AUTOSAR XML (schema 4-0-3)
package /ComponentTypes
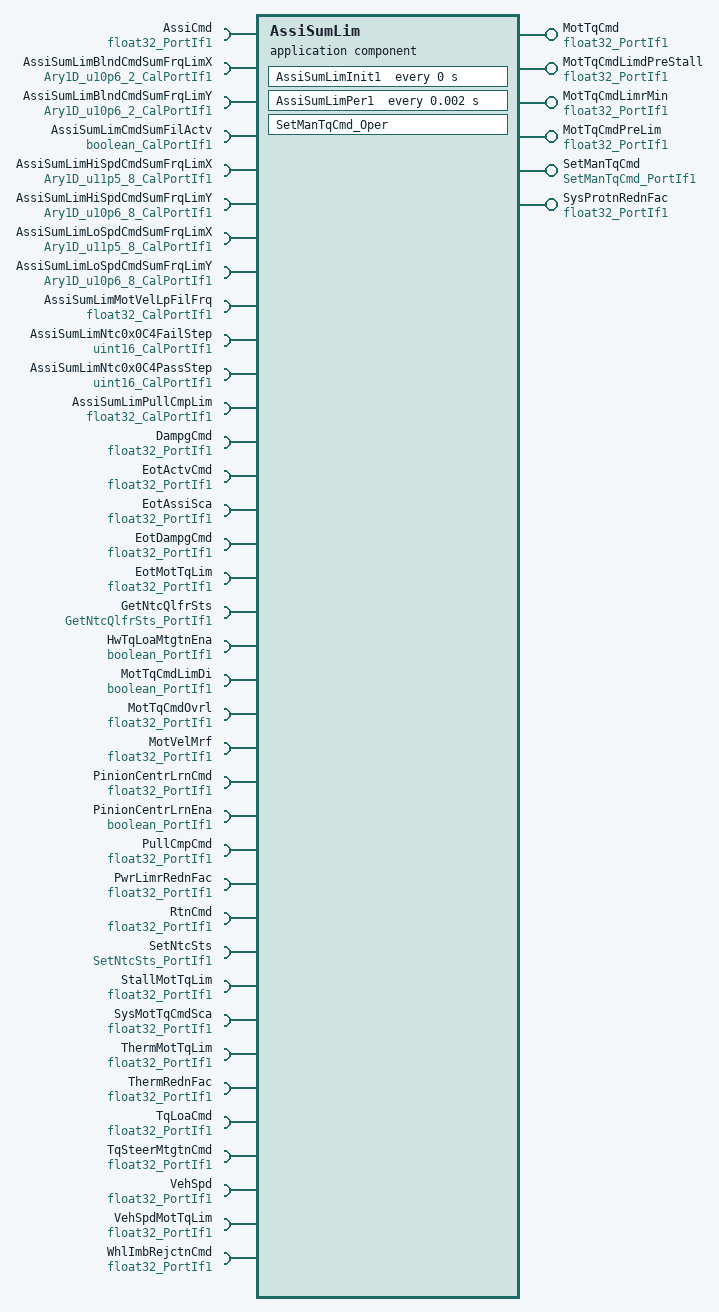
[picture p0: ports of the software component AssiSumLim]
  application sw component type AssiSumLim
    6 x provide port:
      MotTqCmd: nonqueued-sender-com-spec{data-element=Val, init-value=0}, provided-interface=float32_PortIf1
      MotTqCmdLimdPreStall: nonqueued-sender-com-spec{data-element=Val, init-value=0}, provided-interface=float32_PortIf1
      MotTqCmdLimrMin: nonqueued-sender-com-spec{data-element=Val, init-value=8.8}, provided-interface=float32_PortIf1
      MotTqCmdPreLim: nonqueued-sender-com-spec{data-element=Val, init-value=0}, provided-interface=float32_PortIf1
      SetManTqCmd: server-com-spec{operation=Oper, queue-length=1}, provided-interface=SetManTqCmd_PortIf1
      SysProtnRednFac: nonqueued-sender-com-spec{data-element=Val, init-value=0}, provided-interface=float32_PortIf1
    37 x require port:
      AssiCmd: nonqueued-receiver-com-spec{data-element=Val, filter=data-filter-type=ALWAYS, init-value=0}, required-interface=float32_PortIf1
      AssiSumLimBlndCmdSumFrqLimX: parameter-require-com-spec{init-value=[0, 32704], parameter=Ary1D}, required-interface=Ary1D_u10p6_2_CalPortIf1
      AssiSumLimBlndCmdSumFrqLimY: parameter-require-com-spec{init-value=[64, 0], parameter=Ary1D}, required-interface=Ary1D_u10p6_2_CalPortIf1
      AssiSumLimCmdSumFilActv: parameter-require-com-spec{init-value=1, parameter=Logl}, required-interface=boolean_CalPortIf1
      AssiSumLimHiSpdCmdSumFrqLimX: parameter-require-com-spec{init-value=[0, 3200, 8000, 9600, 16000, 24000, 32000, 43200], parameter=Ary1D}, required-interface=Ary1D_u11p5_8_CalPortIf1
      AssiSumLimHiSpdCmdSumFrqLimY: parameter-require-com-spec{init-value=8 x 32000, parameter=Ary1D}, required-interface=Ary1D_u10p6_8_CalPortIf1
      AssiSumLimLoSpdCmdSumFrqLimX: parameter-require-com-spec{init-value=[0, 3200, 8000, 9600, 16000, 24000, 32000, 43200], parameter=Ary1D}, required-interface=Ary1D_u11p5_8_CalPortIf1
      AssiSumLimLoSpdCmdSumFrqLimY: parameter-require-com-spec{init-value=8 x 32000, parameter=Ary1D}, required-interface=Ary1D_u10p6_8_CalPortIf1
      AssiSumLimMotVelLpFilFrq: parameter-require-com-spec{init-value=100, parameter=Val}, required-interface=float32_CalPortIf1
      AssiSumLimNtc0x0C4FailStep: parameter-require-com-spec{init-value=65535, parameter=Val}, required-interface=uint16_CalPortIf1
      AssiSumLimNtc0x0C4PassStep: parameter-require-com-spec{init-value=65535, parameter=Val}, required-interface=uint16_CalPortIf1
      AssiSumLimPullCmpLim: parameter-require-com-spec{init-value=8.8, parameter=Val}, required-interface=float32_CalPortIf1
      DampgCmd: nonqueued-receiver-com-spec{data-element=Val, filter=data-filter-type=ALWAYS, init-value=0}, required-interface=float32_PortIf1
      EotActvCmd: nonqueued-receiver-com-spec{data-element=Val, filter=data-filter-type=ALWAYS, init-value=0}, required-interface=float32_PortIf1
      EotAssiSca: nonqueued-receiver-com-spec{data-element=Val, filter=data-filter-type=ALWAYS, init-value=1}, required-interface=float32_PortIf1
      EotDampgCmd: nonqueued-receiver-com-spec{data-element=Val, filter=data-filter-type=ALWAYS, init-value=0}, required-interface=float32_PortIf1
      EotMotTqLim: nonqueued-receiver-com-spec{data-element=Val, filter=data-filter-type=ALWAYS, init-value=8.8}, required-interface=float32_PortIf1
      GetNtcQlfrSts: client-com-spec=Oper, required-interface=GetNtcQlfrSts_PortIf1
      HwTqLoaMtgtnEna: nonqueued-receiver-com-spec{data-element=Logl, filter=data-filter-type=ALWAYS, init-value=0}, required-interface=boolean_PortIf1
      MotTqCmdLimDi: nonqueued-receiver-com-spec{data-element=Logl, filter=data-filter-type=ALWAYS, init-value=0}, required-interface=boolean_PortIf1
      MotTqCmdOvrl: nonqueued-receiver-com-spec{data-element=Val, filter=data-filter-type=ALWAYS, init-value=0}, required-interface=float32_PortIf1
      MotVelMrf: nonqueued-receiver-com-spec{data-element=Val, filter=data-filter-type=ALWAYS, init-value=0}, required-interface=float32_PortIf1
      PinionCentrLrnCmd: nonqueued-receiver-com-spec{data-element=Val, filter=data-filter-type=ALWAYS, init-value=0}, required-interface=float32_PortIf1
      PinionCentrLrnEna: nonqueued-receiver-com-spec{data-element=Logl, filter=data-filter-type=ALWAYS, init-value=0}, required-interface=boolean_PortIf1
      PullCmpCmd: nonqueued-receiver-com-spec{data-element=Val, filter=data-filter-type=ALWAYS, init-value=0}, required-interface=float32_PortIf1
      PwrLimrRednFac: nonqueued-receiver-com-spec{data-element=Val, filter=data-filter-type=ALWAYS, init-value=0}, required-interface=float32_PortIf1
      RtnCmd: nonqueued-receiver-com-spec{data-element=Val, filter=data-filter-type=ALWAYS, init-value=0}, required-interface=float32_PortIf1
      SetNtcSts: client-com-spec=Oper, required-interface=SetNtcSts_PortIf1
      StallMotTqLim: nonqueued-receiver-com-spec{data-element=Val, filter=data-filter-type=ALWAYS, init-value=8.8}, required-interface=float32_PortIf1
      SysMotTqCmdSca: nonqueued-receiver-com-spec{data-element=Val, filter=data-filter-type=ALWAYS, init-value=1}, required-interface=float32_PortIf1
      ThermMotTqLim: nonqueued-receiver-com-spec{data-element=Val, filter=data-filter-type=ALWAYS, init-value=8.8}, required-interface=float32_PortIf1
      ThermRednFac: nonqueued-receiver-com-spec{data-element=Val, filter=data-filter-type=ALWAYS, init-value=0}, required-interface=float32_PortIf1
      TqLoaCmd: nonqueued-receiver-com-spec{data-element=Val, filter=data-filter-type=ALWAYS, init-value=0}, required-interface=float32_PortIf1
      TqSteerMtgtnCmd: nonqueued-receiver-com-spec{data-element=Val, filter=data-filter-type=ALWAYS, init-value=0}, required-interface=float32_PortIf1
      VehSpd: nonqueued-receiver-com-spec{data-element=Val, filter=data-filter-type=ALWAYS, init-value=0}, required-interface=float32_PortIf1
      VehSpdMotTqLim: nonqueued-receiver-com-spec{data-element=Val, filter=data-filter-type=ALWAYS, init-value=8.8}, required-interface=float32_PortIf1
      WhlImbRejctnCmd: nonqueued-receiver-com-spec{data-element=Val, filter=data-filter-type=ALWAYS, init-value=0}, required-interface=float32_PortIf1
    behavior AssiSumLim_InternalBehavior
      ar-typed-per-instance-memorys:
        data CmdSumInpPrev: sw-calibration-access=READ-ONLY, type=float32
        data CmdSumOutpPrev: sw-calibration-access=READ-ONLY, type=float32
        data MotVelFilLp: sw-calibration-access=READ-ONLY, type=FilLpRec1
      timing event AssiSumLim_InitEvent: start-on-event=AssiSumLimInit1, period=0
      timing event TMT_AssiSumLimPer1: start-on-event=AssiSumLimPer1, period=0.002
      operation invoked event OIT_SetManTqCmd_Oper_SetManTqCmd_Oper: start-on-event=SetManTqCmd_Oper, operation=SetManTqCmd.Oper
      explicit-inter-runnable-variables:
        data ProcdManTqCmd: type=float32, init-value=0
        data ProcdManTqCmdEna: type=boolean, init-value=0
      port-api-options:
        enable-take-address=false, indirect-api=false, port=AssiCmd
        enable-take-address=false, indirect-api=false, port=AssiSumLimBlndCmdSumFrqLimX
        enable-take-address=false, indirect-api=false, port=AssiSumLimBlndCmdSumFrqLimY
        enable-take-address=false, indirect-api=false, port=AssiSumLimCmdSumFilActv
        enable-take-address=false, indirect-api=false, port=AssiSumLimHiSpdCmdSumFrqLimX
        enable-take-address=false, indirect-api=false, port=AssiSumLimHiSpdCmdSumFrqLimY
        enable-take-address=false, indirect-api=false, port=AssiSumLimLoSpdCmdSumFrqLimX
        enable-take-address=false, indirect-api=false, port=AssiSumLimLoSpdCmdSumFrqLimY
        enable-take-address=false, indirect-api=false, port=AssiSumLimMotVelLpFilFrq
        enable-take-address=false, indirect-api=false, port=AssiSumLimNtc0x0C4FailStep
        enable-take-address=false, indirect-api=false, port=AssiSumLimNtc0x0C4PassStep
        enable-take-address=false, indirect-api=false, port=AssiSumLimPullCmpLim
        enable-take-address=false, indirect-api=false, port=DampgCmd
        enable-take-address=false, indirect-api=false, port=EotActvCmd
        enable-take-address=false, indirect-api=false, port=EotAssiSca
        enable-take-address=false, indirect-api=false, port=EotDampgCmd
        enable-take-address=false, indirect-api=false, port=EotMotTqLim
        enable-take-address=false, indirect-api=false, port=GetNtcQlfrSts
        enable-take-address=false, indirect-api=false, port=HwTqLoaMtgtnEna
        enable-take-address=false, indirect-api=false, port=MotTqCmd
        enable-take-address=false, indirect-api=false, port=MotTqCmdLimDi
        enable-take-address=false, indirect-api=false, port=MotTqCmdLimdPreStall
        enable-take-address=false, indirect-api=false, port=MotTqCmdLimrMin
        enable-take-address=false, indirect-api=false, port=MotTqCmdOvrl
        enable-take-address=false, indirect-api=false, port=MotTqCmdPreLim
        enable-take-address=false, indirect-api=false, port=RtnCmd
        enable-take-address=false, indirect-api=false, port=SetManTqCmd
        enable-take-address=false, indirect-api=false, port=SetNtcSts
        enable-take-address=false, indirect-api=false, port=SysMotTqCmdSca
        enable-take-address=false, indirect-api=false, port=SysProtnRednFac
        enable-take-address=false, indirect-api=false, port=TqLoaCmd
        enable-take-address=false, indirect-api=false, port=TqSteerMtgtnCmd
        enable-take-address=false, indirect-api=false, port=VehSpdMotTqLim
        enable-take-address=false, indirect-api=false, port=WhlImbRejctnCmd
      runnable AssiSumLimInit1
        sync call SC_SetNtcSts_Oper: operation=SetNtcSts.Oper, timeout=0
      runnable AssiSumLimPer1
        data-receive-point-by-arguments:
          24 x access:
            REC_AssiCmd_Val: accessed-variable=AssiCmd.Val
            REC_DampgCmd_Val: accessed-variable=DampgCmd.Val
            REC_EotActvCmd_Val: accessed-variable=EotActvCmd.Val
            REC_EotAssiSca_Val: accessed-variable=EotAssiSca.Val
            REC_EotDampgCmd_Val: accessed-variable=EotDampgCmd.Val
            REC_EotMotTqLim_Val: accessed-variable=EotMotTqLim.Val
            REC_HwTqLoaMtgtnEna_Logl: accessed-variable=HwTqLoaMtgtnEna.Logl
            REC_MotTqCmdLimDi_Logl: accessed-variable=MotTqCmdLimDi.Logl
            REC_MotTqCmdOvrl_Val: accessed-variable=MotTqCmdOvrl.Val
            REC_MotVelMrf_Val: accessed-variable=MotVelMrf.Val
            REC_PinionCentrLrnCmd_Val: accessed-variable=PinionCentrLrnCmd.Val
            REC_PinionCentrLrnEna_Logl: accessed-variable=PinionCentrLrnEna.Logl
            REC_PullCmpCmd_Val: accessed-variable=PullCmpCmd.Val
            REC_PwrLimrRednFac_Val: accessed-variable=PwrLimrRednFac.Val
            REC_RtnCmd_Val: accessed-variable=RtnCmd.Val
            REC_StallMotTqLim_Val: accessed-variable=StallMotTqLim.Val
            REC_SysMotTqCmdSca_Val: accessed-variable=SysMotTqCmdSca.Val
            REC_ThermMotTqLim_Val: accessed-variable=ThermMotTqLim.Val
            REC_ThermRednFac_Val: accessed-variable=ThermRednFac.Val
            REC_TqLoaCmd_Val: accessed-variable=TqLoaCmd.Val
            REC_TqSteerMtgtnCmd_Val: accessed-variable=TqSteerMtgtnCmd.Val
            REC_VehSpd_Val: accessed-variable=VehSpd.Val
            REC_VehSpdMotTqLim_Val: accessed-variable=VehSpdMotTqLim.Val
            REC_WhlImbRejctnCmd_Val: accessed-variable=WhlImbRejctnCmd.Val
        data-send-points:
          5 x access:
            SEND_MotTqCmd_Val: accessed-variable=MotTqCmd.Val
            SEND_MotTqCmdLimdPreStall_Val: accessed-variable=MotTqCmdLimdPreStall.Val
            SEND_MotTqCmdLimrMin_Val: accessed-variable=MotTqCmdLimrMin.Val
            SEND_MotTqCmdPreLim_Val: accessed-variable=MotTqCmdPreLim.Val
            SEND_SysProtnRednFac_Val: accessed-variable=SysProtnRednFac.Val
        read-local-variables:
          access READ_ProcdManTqCmd: accessed-variable=ProcdManTqCmd
          access READ_ProcdManTqCmdEna: accessed-variable=ProcdManTqCmdEna
        sync call SC_GetNtcQlfrSts_Oper: operation=GetNtcQlfrSts.Oper, timeout=0
        sync call SC_SetNtcSts_Oper: operation=SetNtcSts.Oper, timeout=0
      runnable SetManTqCmd_Oper: can-be-invoked-concurrently=true
        data-receive-point-by-arguments:
          access REC_VehSpd_Val: accessed-variable=VehSpd.Val
        written-local-variables:
          access WRITE_ProcdManTqCmd: accessed-variable=ProcdManTqCmd
          access WRITE_ProcdManTqCmdEna: accessed-variable=ProcdManTqCmdEna
  swc implementation AssiSumLim_Implementation: behavior=AssiSumLim_InternalBehavior
    code-descriptors:
      code Default: artifact-descriptors=autosar-engineering-object={short-label=Default, category=SWSRC}
